# ADSP-2183xW_LPC register map
Vendor: Analog Devices; Series: ADSP-2183xW_LPC; File version: 3.0.3.517
CPU: 
Registers are 32-bit, read-write, reset 0x0 unless marked. A register's access mark holds for its fields unless they carry their own. Offsets are from the block's base; [hi:lo] are bit positions; {n}, {i} and the like mark numbered series; 'fields as' and 'values as' point back to an identical list.

## SMPU11 — The System Memory Protection Unit
Base 0x310A1000
Same registers: SMPU12 0x31012000
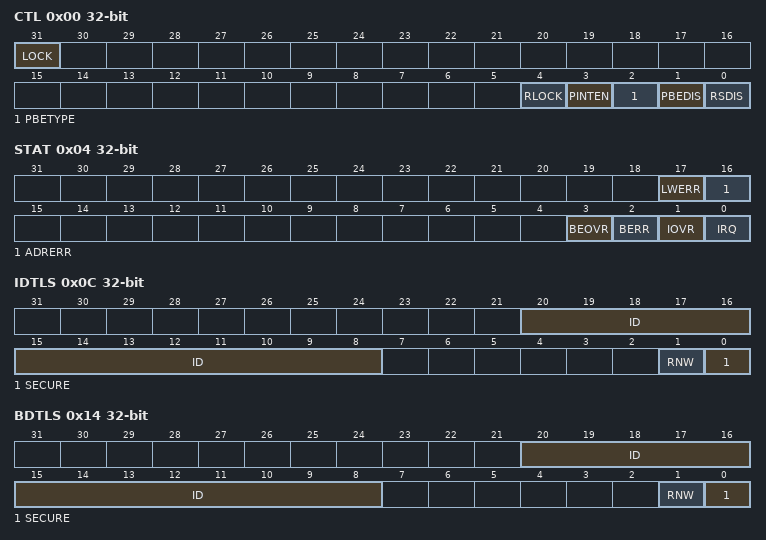
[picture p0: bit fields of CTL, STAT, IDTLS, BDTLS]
0x00 CTL — SMPU Control Register
  [31] LOCK — Lock Bit
  [4] RLOCK — RCTLn, RADDRn, RIDxn and RIDMxn Registers Lock Bit
  [3] PINTEN — Protection Violation Interrupt Enable
    0=PINTDIS (Protection Violation IRQ Disable.); 1=PINTEN (Protection Violation IRQ Enable.)
  [2] PBETYPE — Protection Violation Bus Error Type
    0=DECERR (Decode Error Type.); 1=SLVERR (Completer Error Type.)
  [1] PBEDIS — Protection Violation Bus Error Disable
    0=PBEEN (Bus Error Generation Enable.); 1=PBEDIS (Bus Error Generation Disable.)
  [0] RSDIS — Read Speculation Disable
    0=RSEN (Read Speculation Enable.); 1=RSDIS (Read Speculation Disable.)
0x04 STAT — SMPU Status Register
  [17] LWERR — Lock Write Error
    0=NOLWERR (No Lock Write Error); 1=LWERR (Lock Write Error)
  [16] ADRERR — Address Error
    0=NOADRERR (No Address Error); 1=ADRERR (Address Error)
  [3] BEOVR — Bus Error Overrun
    0=NOBEOVR (No Bus Error overrun); 1=BEOVR (Bus Error overrun has occurred)
  [2] BERR — Bus Error
    0=NOBERR (No Bus Error since this bit has been cleared); 1=BERR (Bus Error has been generated)
  [1] IOVR — Interrupt Overrun
    0=NOIOVR (No Interrupt overrun); 1=IOVR (Interrupt overrun has occurred)
  [0] IRQ — Interrupt Request
    0=NOIRQ (No Interrupt since this bit has been cleared); 1=IRQ (Interrupt has been generated)
0x08 IADDR — Interrupt Address Register
  [31:0] VALUE ro — Interrupt Address
0x0C IDTLS — Interrupt Details Register
  [20:8] ID ro — ID of Transaction
  [1] RNW ro — Read/Write Status
    0=WRITE (Transaction that caused last signaled interrupt was a write); 1=READ (Transaction that caused last signaled interrupt was a read)
  [0] SECURE ro — Secure Status
    0=NONSECURE (Transaction that caused last signaled interrupt was non-secure); 1=SECURE (Transaction that caused last signaled interrupt was secure)
0x10 BADDR — Bus Error Address Register
  [31:0] VALUE ro — Bus Error Address
0x14 BDTLS — Bus Error Details Register
  [20:8] ID ro — ID of Transaction
  [1] RNW ro — Read/Write Status
    0=WRITE (Transaction that caused last bus error was a write); 1=READ (Transaction that caused last bus error was a read)
  [0] SECURE ro — Secure Status Register
    0=NONSECURE (Transaction that caused last bus error was non-secure); 1=SECURE (Transaction that caused last bus error was secure)
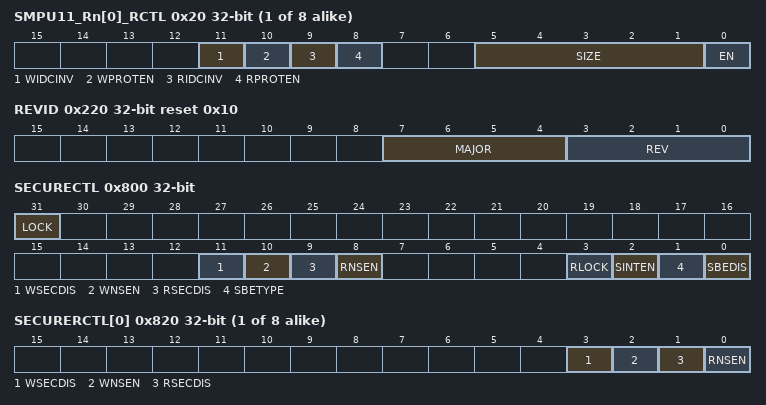
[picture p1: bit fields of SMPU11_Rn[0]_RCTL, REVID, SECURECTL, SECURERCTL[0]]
{0x20+0x18*i} SMPU11_Rn[{i}]_RCTL (i=0..7) — Region n Control Register
  [11] WIDCINV — Write Transaction ID Compare Invert
  [10] WPROTEN — Write Transaction Protection Enable
    0=WPROTDIS (Write transaction ID-based protection disabled); 1=WPROTEN (Write transaction ID-based protection enabled)
  [9] RIDCINV — Read Transaction ID Compare Invert
  [8] RPROTEN — Read Transaction Protection Enable
    0=RPROTDIS (Read transaction ID-based protection disabled); 1=RPROTEN (Read transaction ID-based protection enabled)
  [5:1] SIZE — Memory Region Size
  [0] EN — Region Enable
{0x24+0x18*i} SMPU11_Rn[{i}]_RADDR (i=0..7) — Region n Address Register
  [31:12] BADDR range 0x00000000..0x000FFFFF — Region n Base Address 20 Most Significant Bits
{0x28+0x18*i} SMPU11_Rn[{i}]_RIDA (i=0..7) — Region n ID A Register
  [12:0] ID range 0x00000000..0x00001FFF — Region n ID Register A
{0x2C+0x18*i} SMPU11_Rn[{i}]_RIDMSKA (i=0..7) — Region n ID Mask A Register
  [12:0] MSK range 0x00000000..0x00001FFF — Region n ID Mask Register A
{0x30+0x18*i} SMPU11_Rn[{i}]_RIDB (i=0..7) — Region n ID B Register
  [12:0] ID range 0x00000000..0x00001FFF — Region n ID Register B
{0x34+0x18*i} SMPU11_Rn[{i}]_RIDMSKB (i=0..7) — Region n ID Mask B Register
  [12:0] MSK range 0x00000000..0x00001FFF — Region n ID Mask Register B
0x220 REVID reset 0x10 — SMPU Revision ID Register
  [7:4] MAJOR ro — Major Version ID
  [3:0] REV ro — Incremental Version ID
0x800 SECURECTL — SMPU Control Secure Accesses Register
  [31] LOCK — Lock Bit
  [11] WSECDIS — Secure Write Transaction Disable
    0=WSECEN (Enable secure write transactions); 1=WSECDIS (Disable secure write transactions)
  [10] WNSEN — Non-secure Write Transaction Enable
    0=WNSDIS (Disable non-secure writes); 1=WNSEN (Enable non-secure writes)
  [9] RSECDIS — Secure Read Transaction Disable
    0=RSECEN (Enable secure read transactions); 1=RSECDIS (Disable secure read transactions)
  [8] RNSEN — Non-secure Read Transaction Enable
    0=RNSDIS (Disable non-secure read transactions); 1=RNSEN (Enable non-secure read transactions)
  [3] RLOCK — Secure Region Registers Lock Bit
    0=RLOCKDIS (Disable write-protection on secure region registers); 1=RLOCKEN (Enable write-protection on secure region registers)
  [2] SINTEN — Security Violation Interrupt Enable
    0=SINTDIS (Disable security settings violation interrupt); 1=SINTEN (Enable security settings violation interrupt)
  [1] SBETYPE — Security Violation Bus Error Type
    0=DECERR (Decode error); 1=SLVERR (Completer error)
  [0] SBEDIS — Security Violation Bus Error Disable
    0=SBEEN (Enable bus error); 1=SBEDIS (Disable bus error)
{0x820+4i} SECURERCTL[{i}] (i=0..7) — Region n Control Secure Accesses Register
  [3] WSECDIS — Secure Write Transaction Disable
    0=WSECEN (Enable secure write transactions to this region); 1=WSECDIS (Disable secure write transactions to this region)
  [2] WNSEN — Non-secure Write Transaction Enable
    0=WNSDIS (Disable non-secure write transactions to this region); 1=WNSEN (Enable non-secure write transactions to this region)
  [1] RSECDIS — Secure Read Transaction Disable
    0=RSECEN (Enable secure read transactions to this region); 1=RSECDIS (Disable secure read transactions to this region)
  [0] RNSEN — Non-secure Read Transaction Enable
    0=RNSDIS (Disable non-secure read transactions to this region); 1=RNSEN (Enable non-secure read transactions to this region)

## SMPU2 — The System Memory Protection Unit
Base 0x31083000
Same registers: SMPU4 0x31085000
Registers as SMPU11 (with SMPU11 read as SMPU2); these are added or differ:
0x1A0 SMPU2_EXAn[0]_EXACADD — Exclusive Access IDn Address
  [31:0] VALUE ro
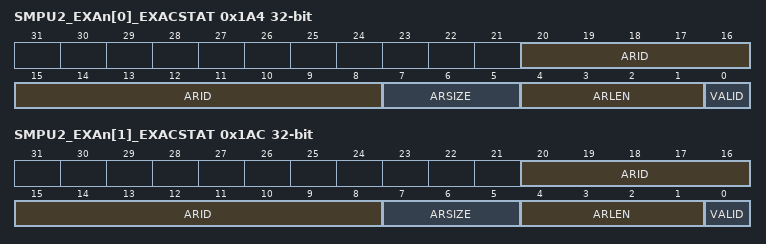
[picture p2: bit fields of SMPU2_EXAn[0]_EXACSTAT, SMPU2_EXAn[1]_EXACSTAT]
0x1A4 SMPU2_EXAn[0]_EXACSTAT — Exclusive Access Status
  [20:8] ARID ro — Exclusive Access ID
  [7:5] ARSIZE ro — Exclusive Access Read Size
  [4:1] ARLEN ro — Exclusive Access Read Length
  [0] VALID ro — Valid Exclusive Access Read
0x1A8 SMPU2_EXAn[1]_EXACADD — Exclusive Access IDn Address
  [31:0] VALUE ro
0x1AC SMPU2_EXAn[1]_EXACSTAT — Exclusive Access Status
  fields as SMPU2_EXAn[0]_EXACSTAT

## SMPU3 — The System Memory Protection Unit
Base 0x31084000
Same registers: SMPU5 0x31086000, SMPU6 0x31087000
Registers as SMPU11 (with SMPU11 read as SMPU3).

## SMPU9 — The System Memory Protection Unit
Base 0x310A0000
Registers as SMPU2 (with SMPU2 read as SMPU9).

## SMPU13 — The System Memory Protection Unit
Base 0x3114A000
Registers as SMPU11 (with SMPU11 read as SMPU13).
